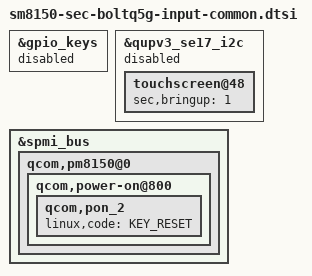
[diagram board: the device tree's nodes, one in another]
/* Copyright (c) 2016-2017, The Linux Foundation. All rights reserved.
 *
 * This program is free software; you can redistribute it and/or modify
 * it under the terms of the GNU General Public License version 2 and
 * only version 2 as published by the Free Software Foundation.
 *
 * This program is distributed in the hope that it will be useful,
 * but WITHOUT ANY WARRANTY; without even the implied warranty of
 * MERCHANTABILITY or FITNESS FOR A PARTICULAR PURPOSE.  See the
 * GNU General Public License for more details.
 */

#include "sm8150-sec-beyondqlte-input-common.dtsi"

&gpio_keys {
	status = "disabled";
};

&qupv3_se17_i2c {
	status = "disabled";
	touchscreen@48 {
		sec,bringup = <1>;
	};
};

&spmi_bus {
	qcom,pm8150@0 {
		qcom,power-on@800 {
			qcom,pon_2 {
				linux,code = <KEY_RESET>;
			};
		};
	};
};
